# AVR32SD32 device description
Architecture: AVR8X; Family: AVR
Registers are 8-bit, read-write, reset 0x0 unless marked. A register's access mark holds for its fields unless they carry their own. Offsets are from the block's base; [hi:lo] are bit positions; 'fields as' and 'values as' point back to an identical list.

## RAMCTRL — RAM Controller
Instances: RAMCTRL 0x0E30
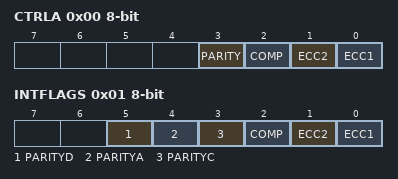
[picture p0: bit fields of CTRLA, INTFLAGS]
0x00 CTRLA — Control A
  [3] PARITY — Inject Parity Error
  [2] COMP — Inject ECC Compare Error
  [1] ECC2 — Inject 2-bit ECC Error
  [0] ECC1 — Inject 1-bit ECC Error
0x01 INTFLAGS — Interrupt Flags
  [5] PARITYD — Parity Error Detected on Write Data
  [4] PARITYA — Parity Error Detected on Address
  [3] PARITYC — Parity Error Detected on Control
  [2] COMP — Comparator Mismatch Error Detected
  [1] ECC2 — ECC Multibit Error Detected
  [0] ECC1 — ECC 1-bit Error Detected
0x02 ADDR 16-bit ro — ECC Address
0x04 SYNDROME ro — ECC Syndrome

## RSTCTRL — Reset controller
Instances: RSTCTRL 0x0040
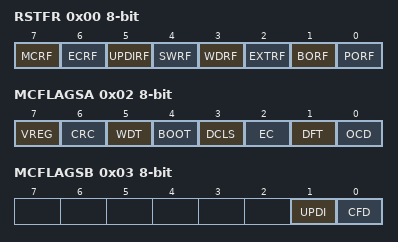
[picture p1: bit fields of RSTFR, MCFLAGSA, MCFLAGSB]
0x00 RSTFR reset not defined — Reset Flags
  [7] MCRF — Machine Check Reset Flag
  [6] ECRF — Error Controller Reset Flag
  [5] UPDIRF — UPDI Reset Flag
  [4] SWRF — Software Reset Flag
  [3] WDRF — Watchdog Reset Flag
  [2] EXTRF — External Reset Flag
  [1] BORF — Brown-out Detector Reset Flag
  [0] PORF — Power-On Reset Flag
0x01 SWRR — Software Reset
  [0] SWRST
0x02 MCFLAGSA reset not defined — Machine Check Flags A
  [7] VREG — Voltage Regulator Monitor
  [6] CRC — CRC Scan Error
  [5] WDT — WDT Clock Failure Monitor
  [4] BOOT — Boot Error Detected
  [3] DCLS — Dual Core Lockstep Comparator Mismatch
  [2] EC — Error Controller Internal Error
  [1] DFT — Design-for-Test Mechanism Enabled
  [0] OCD — OCD System Enabled
0x03 MCFLAGSB reset not defined — Machine Check Flags B
  [1] UPDI — Illegal UPDI bus activity detected
  [0] CFD — Clock Failure Detect

## RTC — Real-Time Counter
Instances: RTC 0x0140
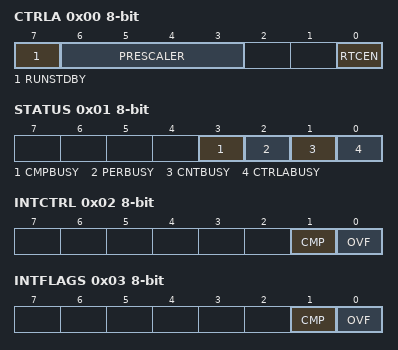
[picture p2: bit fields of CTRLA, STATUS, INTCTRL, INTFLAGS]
0x00 CTRLA — Control A
  [7] RUNSTDBY — Run In Standby
  [6:3] PRESCALER — Prescaling Factor
    0=DIV1 (RTC Clock / 1); 1=DIV2 (RTC Clock / 2); 2=DIV4 (RTC Clock / 4); 3=DIV8 (RTC Clock / 8); 4=DIV16 (RTC Clock / 16); 5=DIV32 (RTC Clock / 32); 6=DIV64 (RTC Clock / 64); 7=DIV128 (RTC Clock / 128); 8=DIV256 (RTC Clock / 256); 9=DIV512 (RTC Clock / 512); 10=DIV1024 (RTC Clock / 1024); 11=DIV2048 (RTC Clock / 2048); 12=DIV4096 (RTC Clock / 4096); 13=DIV8192 (RTC Clock / 8192); 14=DIV16384 (RTC Clock / 16384); 15=DIV32768 (RTC Clock / 32768)
  [0] RTCEN — Enable
0x01 STATUS ro
  [3] CMPBUSY — Comparator Synchronization Busy Flag
  [2] PERBUSY — Period Synchronization Busy Flag
  [1] CNTBUSY — Count Synchronization Busy Flag
  [0] CTRLABUSY — CTRLA Synchronization Busy Flag
0x02 INTCTRL — Interrupt Control
  [1] CMP — Compare Match Interrupt enable
  [0] OVF — Overflow Interrupt enable
0x03 INTFLAGS — Interrupt Flags
  [1] CMP — Compare Match Interrupt
  [0] OVF — Overflow Interrupt Flag
0x04 TEMP reset not defined — Temporary
0x05 DBGCTRL — Debug control
  [0] DBGRUN — Run in debug
0x07 CLKSEL — Clock Select
  [1:0] CLKSEL
    0=OSC32K (32.768 kHz from OSC32K); 1=OSC1K (1.024 kHz from OSC32K); 2=XTAL32K (32.768 kHz from XOSC32K or external clock from XTAL32K1 pin); 3=EXTCLK (External clock from XOSCHF or external clock from the XTALHF1 pin)
0x08 CNT 16-bit reset not defined — Counter
0x0A PER 16-bit reset 0xFFFF — Period
0x0C CMP 16-bit reset not defined — Compare
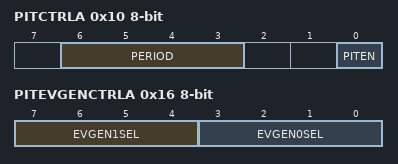
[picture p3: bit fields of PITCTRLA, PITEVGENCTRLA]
0x10 PITCTRLA — PIT Control A
  [6:3] PERIOD
    0=OFF; 1=CYC4 (RTC Clock Cycles 4); 2=CYC8 (RTC Clock Cycles 8); 3=CYC16 (RTC Clock Cycles 16); 4=CYC32 (RTC Clock Cycles 32); 5=CYC64 (RTC Clock Cycles 64); 6=CYC128 (RTC Clock Cycles 128); 7=CYC256 (RTC Clock Cycles 256); 8=CYC512 (RTC Clock Cycles 512); 9=CYC1024 (RTC Clock Cycles 1024); 10=CYC2048 (RTC Clock Cycles 2048); 11=CYC4096 (RTC Clock Cycles 4096); 12=CYC8192 (RTC Clock Cycles 8192); 13=CYC16384 (RTC Clock Cycles 16384); 14=CYC32768 (RTC Clock Cycles 32768)
  [0] PITEN — Enable
0x11 PITSTATUS ro
  [0] CTRLBUSY — CTRLA Synchronization Busy Flag
0x12 PITINTCTRL — PIT Interrupt Control
  [0] PI — Periodic Interrupt
0x13 PITINTFLAGS — PIT Interrupt Flags
  [0] PI — Periodic Interrupt
0x15 PITDBGCTRL — PIT Debug control
  [0] DBGRUN — Run in debug
0x16 PITEVGENCTRLA — PIT Event Generation Control A
  [7:4] EVGEN1SEL — Event Generation 1 Select
    0=OFF (No Event Generated); 1=DIV4 (CLK_RTC divided by 4); 2=DIV8 (CLK_RTC divided by 8); 3=DIV16 (CLK_RTC divided by 16); 4=DIV32 (CLK_RTC divided by 32); 5=DIV64 (CLK_RTC divided by 64); 6=DIV128 (CLK_RTC divided by 128); 7=DIV256 (CLK_RTC divided by 256); 8=DIV512 (CLK_RTC divided by 512); 9=DIV1024 (CLK_RTC divided by 1024); 10=DIV2048 (CLK_RTC divided by 2048); 11=DIV4096 (CLK_RTC divided by 4096); 12=DIV8192 (CLK_RTC divided by 8192); 13=DIV16384 (CLK_RTC divided by 16384); 14=DIV32768 (CLK_RTC divided by 32768)
  [3:0] EVGEN0SEL — Event Generation 0 Select
    values as EVGEN1SEL
